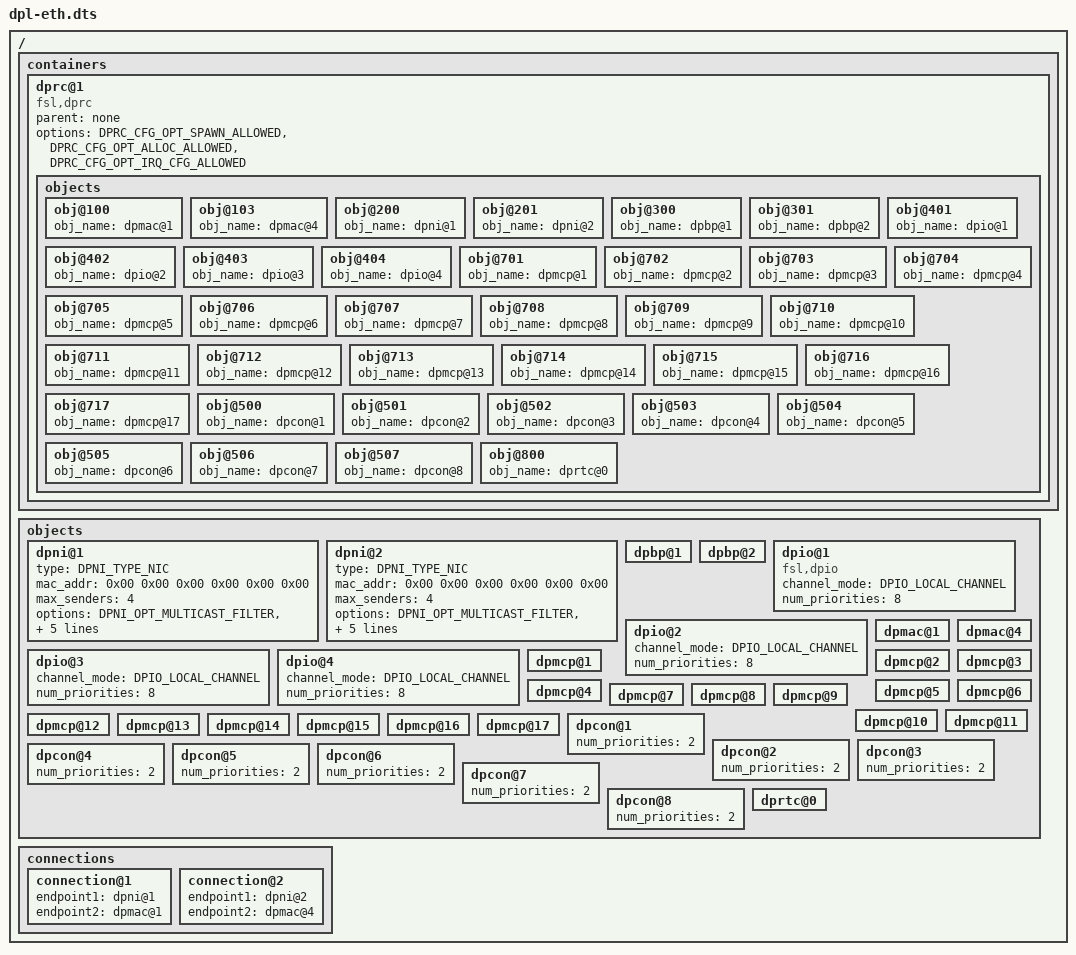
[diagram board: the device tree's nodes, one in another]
/*
 * Copyright 2017 NXP
 *
 * Redistribution and use in source and binary forms, with or without
 * modification, are permitted provided that the following conditions are met:
 *   * Redistributions of source code must retain the above copyright
 *     notice, this list of conditions and the following disclaimer.
 *   * Redistributions in binary form must reproduce the above copyright
 *     notice, this list of conditions and the following disclaimer in the
 *     documentation and/or other materials provided with the distribution.
 *   * Neither the name of the above-listed copyright holders nor the
 *     names of any contributors may be used to endorse or promote products
 *     derived from this software without specific prior written permission.
 *
 * THIS SOFTWARE IS PROVIDED BY THE COPYRIGHT HOLDERS AND CONTRIBUTORS "AS IS"
 * AND ANY EXPRESS OR IMPLIED WARRANTIES, INCLUDING, BUT NOT LIMITED TO, THE
 * IMPLIED WARRANTIES OF MERCHANTABILITY AND FITNESS FOR A PARTICULAR PURPOSE
 * ARE DISCLAIMED. IN NO EVENT SHALL THE COPYRIGHT HOLDERS OR CONTRIBUTORS BE
 * LIABLE FOR ANY DIRECT, INDIRECT, INCIDENTAL, SPECIAL, EXEMPLARY, OR
 * CONSEQUENTIAL DAMAGES (INCLUDING, BUT NOT LIMITED TO, PROCUREMENT OF
 * SUBSTITUTE GOODS OR SERVICES; LOSS OF USE, DATA, OR PROFITS; OR BUSINESS
 * INTERRUPTION) HOWEVER CAUSED AND ON ANY THEORY OF LIABILITY, WHETHER IN
 * CONTRACT, STRICT LIABILITY, OR TORT (INCLUDING NEGLIGENCE OR OTHERWISE)
 * ARISING IN ANY WAY OUT OF THE USE OF THIS SOFTWARE, EVEN IF ADVISED OF THE
 * POSSIBILITY OF SUCH DAMAGE.
 */
/dts-v1/;
/ {
	/*****************************************************************
         * Containers
         *****************************************************************/
	containers {
		dprc@1 {
			compatible = "fsl,dprc";
			parent = "none";
			options = "DPRC_CFG_OPT_SPAWN_ALLOWED" , "DPRC_CFG_OPT_ALLOC_ALLOWED", "DPRC_CFG_OPT_IRQ_CFG_ALLOWED";
			objects {
				/* ------------- MACs --------------*/
				obj@100 {
					obj_name = "dpmac@1";
				};
				obj@103 {
					obj_name = "dpmac@4";
				};

				/* ------------ DPNIs --------------*/
				obj@200 {
					obj_name = "dpni@1";
				};
				obj@201 {
					obj_name = "dpni@2";
				};

				/* ------------ DPBPs --------------*/
				obj@300 {
					obj_name="dpbp@1";
				};
				obj@301 {
					obj_name="dpbp@2";
				};

				/* ------------ DPIOs --------------*/
				obj@401 {
					obj_name = "dpio@1";
				};
				obj@402 {
					obj_name = "dpio@2";
				};
				obj@403 {
					obj_name = "dpio@3";
				};
				obj@404 {
					obj_name = "dpio@4";
				};

				/* ------------ DPMCPs --------------*/
				obj@701 {
					obj_name="dpmcp@1";
				};
				obj@702 {
					obj_name="dpmcp@2";
				};
				obj@703 {
					obj_name="dpmcp@3";
				};
				obj@704 {
					obj_name="dpmcp@4";
				};
				obj@705 {
					obj_name="dpmcp@5";
				};
				obj@706 {
					obj_name="dpmcp@6";
				};
				obj@707 {
					obj_name="dpmcp@7";
				};
				obj@708 {
					obj_name="dpmcp@8";
				};
				obj@709 {
					obj_name="dpmcp@9";
				};
				obj@710 {
					obj_name="dpmcp@10";
				};
				obj@711 {
					obj_name="dpmcp@11";
				};
				obj@712 {
					obj_name="dpmcp@12";
				};
				obj@713 {
					obj_name="dpmcp@13";
				};
				obj@714 {
					obj_name="dpmcp@14";
				};
				obj@715 {
					obj_name="dpmcp@15";
				};
				obj@716 {
					obj_name="dpmcp@16";
				};
				obj@717 {
					obj_name="dpmcp@17";
				};

				/* ------------ DPCON --------------*/
				obj@500 {
					obj_name="dpcon@1";
				};
				obj@501 {
					obj_name="dpcon@2";
				};
				obj@502 {
					obj_name="dpcon@3";
				};
				obj@503 {
					obj_name="dpcon@4";
				};
				obj@504 {
					obj_name="dpcon@5";
				};
				obj@505 {
					obj_name="dpcon@6";
				};
				obj@506 {
					obj_name="dpcon@7";
				};
				obj@507 {
					obj_name="dpcon@8";
				};

				/* ------------ DPRTC --------------*/
				obj@800 {
					obj_name="dprtc@0";
				};
			};
		};
	};

	/*****************************************************************
         * Objects
         *****************************************************************/
	objects {

		/* ------------ DPNI --------------*/
		dpni@1 {
			type = "DPNI_TYPE_NIC";
			mac_addr = <0x00 0x00 0x00 0x00 0x00 0x00>;
			max_senders = <4>;
			options = "DPNI_OPT_MULTICAST_FILTER", "DPNI_OPT_UNICAST_FILTER", "DPNI_OPT_DIST_HASH", "DPNI_OPT_DIST_FS";
			max_tcs = <1>;
			max_dist_per_tc = <4>;
			max_dist_key_size = <24>;
		};
		dpni@2 {
			type = "DPNI_TYPE_NIC";
			mac_addr = <0x00 0x00 0x00 0x00 0x00 0x00>;
			max_senders = <4>;
			options = "DPNI_OPT_MULTICAST_FILTER", "DPNI_OPT_UNICAST_FILTER", "DPNI_OPT_DIST_HASH", "DPNI_OPT_DIST_FS";
			max_tcs = <1>;
			max_dist_per_tc = <4>;
			max_dist_key_size = <24>;
		};

		/* ------------ DPBP --------------*/
		dpbp@1 {
		};
		dpbp@2 {
		};

		/* ------------ DPIO --------------*/
		dpio@1 {
			compatible = "fsl,dpio";
			channel_mode = "DPIO_LOCAL_CHANNEL";
			num_priorities = <8>;
		};
		dpio@2 {
			channel_mode = "DPIO_LOCAL_CHANNEL";
			num_priorities = <8>;
		};
		dpio@3 {
			channel_mode = "DPIO_LOCAL_CHANNEL";
			num_priorities = <8>;
		};
		dpio@4 {
			channel_mode = "DPIO_LOCAL_CHANNEL";
			num_priorities = <8>;
		};

		/* ------------ DPMAC --------------*/
		dpmac@1 {
		};
		dpmac@4 {
		};

		/* ------------ DPMCP --------------*/
		dpmcp@1 {
		};
		dpmcp@2 {
		};
		dpmcp@3 {
		};
		dpmcp@4 {
		};
		dpmcp@5 {
		};
		dpmcp@6 {
		};
		dpmcp@7 {
		};
		dpmcp@8 {
		};
		dpmcp@9 {
		};
		dpmcp@10 {
		};
		dpmcp@11 {
		};
		dpmcp@12 {
		};
		dpmcp@13 {
		};
		dpmcp@14 {
		};
		dpmcp@15 {
		};
		dpmcp@16 {
		};
		dpmcp@17 {
		};

		/* ------------ DPCON --------------*/
		dpcon@1 {
			num_priorities=<2>;
		};
		dpcon@2 {
			num_priorities=<2>;
		};
		dpcon@3 {
			num_priorities=<2>;
		};
		dpcon@4 {
			num_priorities=<2>;
		};
		dpcon@5 {
			num_priorities=<2>;
		};
		dpcon@6 {
			num_priorities=<2>;
		};
		dpcon@7 {
			num_priorities=<2>;
		};
		dpcon@8 {
			num_priorities=<2>;
		};

		/* ------------ DPRTC --------------*/
		dprtc@0 {
		};
	};

	/*****************************************************************
         * Connections
         *****************************************************************/
	connections {
		connection@1{
			endpoint1 = "dpni@1";
			endpoint2 = "dpmac@1";
		};
		connection@2{
			endpoint1 = "dpni@2";
			endpoint2 = "dpmac@4";
		};
	};
};
